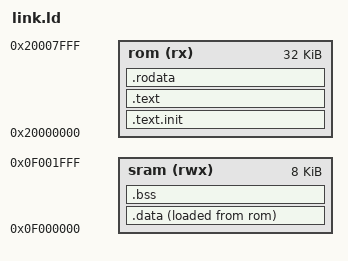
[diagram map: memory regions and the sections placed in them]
/*
 * Linker script for the Raptor FPGA bring-up firmware.
 *
 * Memory map matches the LiteX SoC generated by raptor_tang_mega_138k_pro.py:
 *   ROM  : 0x20000000, 32 KB  (integrated_rom_size = 0x8000)
 *   SRAM : 0x0f000000,  8 KB  (integrated_sram_size = 0x2000)
 *
 * Layout philosophy:
 *   * .text + .rodata + .data load image -> ROM (read-only).
 *   * .data is *copied* by boot.S to SRAM at runtime so writes work.
 *   * .bss + stack live in SRAM.
 *   * Stack grows down from _stack_top (= top of SRAM).
 */

OUTPUT_ARCH(riscv)
ENTRY(_start)

MEMORY {
    rom  (rx)  : ORIGIN = 0x20000000, LENGTH = 32K
    sram (rwx) : ORIGIN = 0x0f000000, LENGTH = 8K
}

SECTIONS {
    /* Reset vector first. */
    .text.init : {
        *(.text.init)
    } > rom

    .text : {
        *(.text)
        *(.text.*)
    } > rom

    .rodata : ALIGN(4) {
        *(.rodata)
        *(.rodata.*)
    } > rom

    /* .data: load image in ROM, runtime copy in SRAM. */
    .data : ALIGN(4) {
        _sdata = .;
        *(.data)
        *(.data.*)
        *(.sdata)
        *(.sdata.*)
        . = ALIGN(4);
        _edata = .;
    } > sram AT > rom

    _sidata = LOADADDR(.data);

    /* End of the loaded ROM image (.text + .rodata + .data load image).
     * Used by the `rom-crc` shell command to compute a CRC over the live
     * ROM contents and compare against the build-time CRC of boot.bin —
     * detects BSRAM read-back corruption (or AXI-fetch path glitches that
     * silently flip bytes). */
    _erom = LOADADDR(.data) + (_edata - _sdata);
    _srom = ORIGIN(rom);

    .bss (NOLOAD) : ALIGN(4) {
        _sbss = .;
        *(.bss)
        *(.bss.*)
        *(.sbss)
        *(.sbss.*)
        *(COMMON)
        . = ALIGN(4);
        _ebss = .;
    } > sram

    /* Stack layout (grows down toward _ebss):
     *   _stack_top      = top of SRAM (main C stack starts here)
     *   _trap_stack_top = main stack top - 0x100  (256 B trap stack just
     *                     below; isolated from main stack so a corrupt
     *                     main sp can't cascade through the trap handler)
     *   ... main stack ...
     *   _ebss
     * The 256-byte trap stack is enough for a few uart_put_hex32 calls
     * since UART code only spills a couple of registers. */
    _stack_top      = ORIGIN(sram) + LENGTH(sram) - 0x100;
    _trap_stack_top = ORIGIN(sram) + LENGTH(sram);

    /DISCARD/ : {
        *(.eh_frame)
        *(.comment)
        *(.riscv.attributes)
        *(.note.*)
    }
}
